# bcm2711_lpa register map
Vendor: BROADCOM; Series: BCM2711; File version: A
CPU: CA72 r0p0, little endian, MPU, FPU, 2 interrupt priority bits
Registers are 32-bit, read-write, reset 0x0 unless marked. A register's access mark holds for its fields unless they carry their own. Offsets are from the block's base; [hi:lo] are bit positions; {n}, {i} and the like mark numbered series; 'fields as' and 'values as' point back to an identical list.

## SPI1 — Aux SPI
Base 0xFE215080
Same registers: SPI2 0xFE2150C0
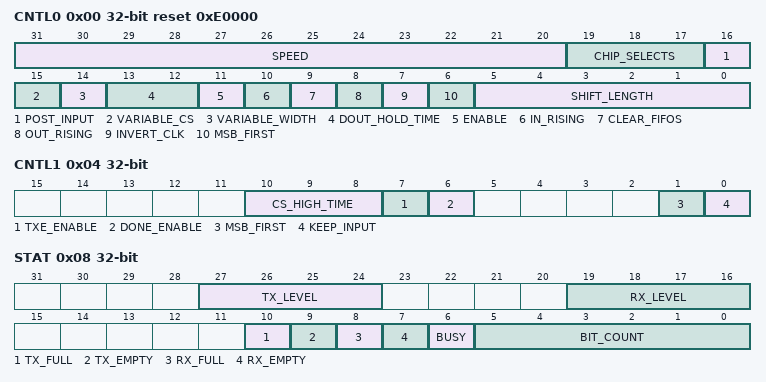
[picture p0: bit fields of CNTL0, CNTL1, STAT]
0x00 CNTL0 reset 0xE0000 — Control 0
  [31:20] SPEED — SPI clock speed. clk = sys / 2 * (SPEED + 1)
  [19:17] CHIP_SELECTS — The CS pattern when active
  [16] POST_INPUT — Post input mode
  [15] VARIABLE_CS — Take CS pattern and data from TX FIFO (along with VARIABLE_WIDTH)
  [14] VARIABLE_WIDTH — Take shift length and data from FIFO
  [13:12] DOUT_HOLD_TIME — Controls extra DOUT hold time in system clock cycles
    0=0; 1=1; 2=4; 3=7
  [11] ENABLE — Enable the interface
  [10] IN_RISING — Data is clocked in on rising edge of CLK
  [9] CLEAR_FIFOS
  [8] OUT_RISING — Data is clocked out on rising edge of CLK
  [7] INVERT_CLK — Idle clock high
  [6] MSB_FIRST — Shift out the most significant bit (MSB) first
  [5:0] SHIFT_LENGTH — Number of bits to shift
0x04 CNTL1 — Control 1
  [10:8] CS_HIGH_TIME — Additional SPI clock cycles where CS is high
  [7] TXE_ENABLE — Enable TX empty interrupt
  [6] DONE_ENABLE — Enable DONE interrupt
  [1] MSB_FIRST — Shift the most significant bit first (MSB)
  [0] KEEP_INPUT — Don't clear the RX shift register before a new transaction
0x08 STAT — Status
  [27:24] TX_LEVEL — Number of entries in TX FIFO
  [19:16] RX_LEVEL — Number of entries in RX FIFO
  [10] TX_FULL — TX FIFO is full
  [9] TX_EMPTY — TX FIFO is empty
  [8] RX_FULL — RX FIFO is full
  [7] RX_EMPTY — RX FIFO is empty
  [6] BUSY — Indicates a transfer is ongoing
  [5:0] BIT_COUNT — Number of bits left to be processed.
0x0C PEEK ro — Read the RXFIFO without removing an entry
  [15:0] DATA — FIFO data access
{0x10+4i} IO{i} (i=0..3) — Writing to the FIFO will deassert CS at the end of the access
  [15:0] DATA — FIFO data access
{0x20+4i} TXHOLD{i} (i=0..3) — Writing to the FIFO will maintain CS at the end of the access
  [15:0] DATA — FIFO data access

## LIC — Broadcom Legacy Interrupt Controller
Base 0xFF800000
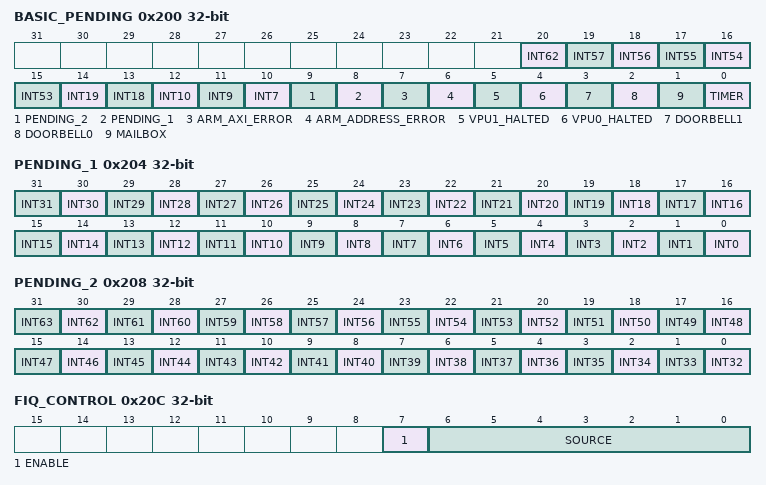
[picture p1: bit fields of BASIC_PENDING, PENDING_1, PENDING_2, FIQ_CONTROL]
0x200 BASIC_PENDING ro — Basic pending info
  [20] INT62 — Interrupt 62
  [n-38] INT{n} (n=53..57) — Interrupt {n}
  [14] INT19 — Interrupt 19
  [13] INT18 — Interrupt 18
  [12] INT10 — Interrupt 10
  [11] INT9 — Interrupt 9
  [10] INT7 — Interrupt 7
  [9] PENDING_2 — One or more bits are set in PENDING_2 (ignores 53 - 57, 62)
  [8] PENDING_1 — One or more bits are set in PENDING_1 (ignores 7, 9, 10, 18, 19)
  [7] ARM_AXI_ERROR
  [6] ARM_ADDRESS_ERROR
  [5] VPU1_HALTED
  [4] VPU0_HALTED
  [3] DOORBELL1
  [2] DOORBELL0
  [1] MAILBOX
  [0] TIMER — ARMC Timer
0x204 PENDING_1 ro — Pending state for interrupts 1 - 31
  [n] INT{n} (n=0..31) — Interrupt {n}
0x208 PENDING_2 ro — Pending state for interrupts 32 - 63
  [n-32] INT{n} (n=32..63) — Interrupt {n}
0x20C FIQ_CONTROL
  [7] ENABLE — FIQ Enable
  [6:0] SOURCE — FIQ Source
    {v}=INT{v} (Interrupt {v}) (v=0..63); 64=TIMER (ARMC Timer); 65=MAILBOX; 66=DOORBELL0; 67=DOORBELL1; 68=VPU0_HALTED; 69=VPU1_HALTED; 70=ARM_ADDRESS_ERROR; 71=ARM_AXI_ERROR
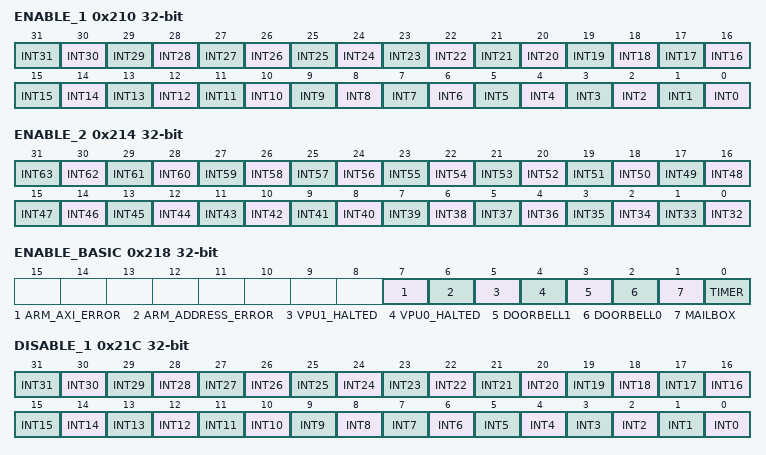
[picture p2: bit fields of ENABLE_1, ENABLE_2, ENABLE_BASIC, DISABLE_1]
0x210 ENABLE_1 write-1-sets — Enable interrupts 1 - 31
  [n] INT{n} (n=0..31) — Interrupt {n}
0x214 ENABLE_2 write-1-sets — Enable interrupts 32 - 63
  [n-32] INT{n} (n=32..63) — Interrupt {n}
0x218 ENABLE_BASIC write-1-sets — Enable basic interrupts
  [7] ARM_AXI_ERROR
  [6] ARM_ADDRESS_ERROR
  [5] VPU1_HALTED
  [4] VPU0_HALTED
  [3] DOORBELL1
  [2] DOORBELL0
  [1] MAILBOX
  [0] TIMER — ARMC Timer
0x21C DISABLE_1 write-1-clears — Disable interrupts 1 - 31
  [n] INT{n} (n=0..31) — Interrupt {n}
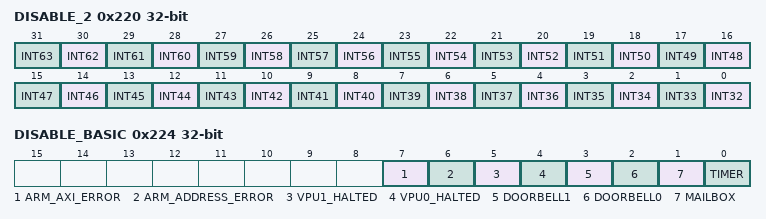
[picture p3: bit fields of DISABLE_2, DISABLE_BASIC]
0x220 DISABLE_2 write-1-clears — Disable interrupts 32 - 63
  [n-32] INT{n} (n=32..63) — Interrupt {n}
0x224 DISABLE_BASIC write-1-clears — Disable basic interrupts
  fields as ENABLE_BASIC
